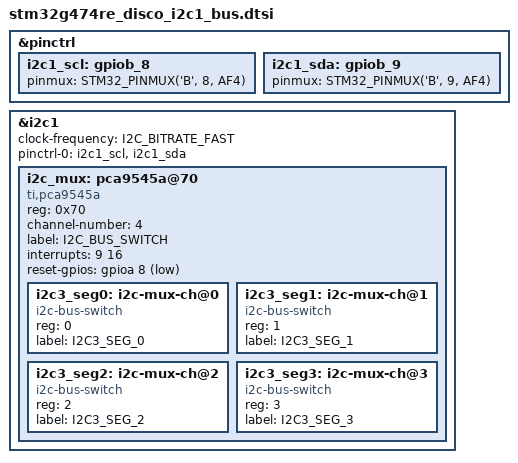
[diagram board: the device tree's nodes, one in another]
/*
 * Copyright (c) 2020 Rohan Dey
 * Copyright (c) 2020 Volodymyr Sirous
 *
 * SPDX-License-Identifier: Apache-2.0
 */


&pinctrl {
  i2c1_scl: gpiob_8 {
    pinmux = <STM32_PINMUX('B', 8, AF4)>;
  };

  i2c1_sda: gpiob_9 {
    pinmux = <STM32_PINMUX('B', 9, AF4)>;
  };
};

&i2c1 {
	status = "okay";
	clock-frequency = <I2C_BITRATE_FAST>;
	pinctrl-0 = <&i2c1_scl &i2c1_sda>;
  
		i2c_mux: pca9545a@70 {
	    	compatible = "ti,pca9545a";
	    	status = "okay";
		    reg = <0x70>;
		    channel-number = <4>;
		    label = "I2C_BUS_SWITCH";
		    interrupts = <9 16>;
		    reset-gpios = <&gpioa 8 GPIO_ACTIVE_LOW>;
		    #address-cells = <1>;
		    #size-cells = <0>;
			/*#channel-cells = <1>;*/
  
		    i2c3_seg0: i2c-mux-ch@0 {
		      compatible = "i2c-bus-switch";
		      #address-cells = <1>;
		      #size-cells = <0>;
		      reg = <0>;
		      label = "I2C3_SEG_0";
		    };
		
		    i2c3_seg1: i2c-mux-ch@1 {
		      compatible = "i2c-bus-switch";
		      #address-cells = <1>;
		      #size-cells = <0>;
		      reg = <1>;
		      label = "I2C3_SEG_1";
		    };
		  
		    i2c3_seg2: i2c-mux-ch@2 {
		      compatible = "i2c-bus-switch";
		      #address-cells = <1>;
		      #size-cells = <0>;
		      reg = <2>;
		      label = "I2C3_SEG_2";
		    };
		
		    i2c3_seg3: i2c-mux-ch@3 {
		      compatible = "i2c-bus-switch";
		      #address-cells = <1>;
		      #size-cells = <0>;
		      reg = <3>;
		      label = "I2C3_SEG_3";
		    };	
	  };
};
